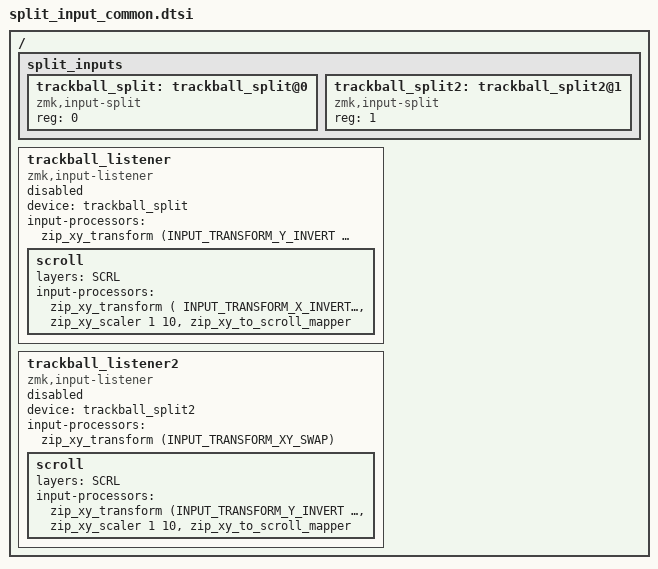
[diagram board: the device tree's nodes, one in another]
#include <dt-bindings/zmk/input_transform.h>
#include <input/processors.dtsi>

#define U_BASE   0
#define U_EXTRA  1
#define U_TAP    2
#define U_BUTTON 3
#define U_NAV    4
#define U_MOUSE  5
#define U_MEDIA  6
#define U_NUM    7
#define U_SYM    8
#define U_FUN    9

/ {
  split_inputs {
    #address-cells = <1>;
    #size-cells = <0>;

    trackball_split: trackball_split@0 {
      compatible = "zmk,input-split";
      reg = <0>;
    };
    trackball_split2: trackball_split2@1 {
      compatible = "zmk,input-split";
      reg = <1>;
    };
  };

  trackball_listener: trackball_listener {
    compatible = "zmk,input-listener";
    status = "disabled";
    device = <&trackball_split>;
    input-processors = <&zip_xy_transform (INPUT_TRANSFORM_Y_INVERT | INPUT_TRANSFORM_X_INVERT | INPUT_TRANSFORM_XY_SWAP )>;
    scroll {
      layers = <SCRL>;
      input-processors = <&zip_xy_transform ( INPUT_TRANSFORM_X_INVERT | INPUT_TRANSFORM_XY_SWAP)>, <&zip_xy_scaler 1 10>, <&zip_xy_to_scroll_mapper>;
    };

  };
  trackball_listener2: trackball_listener2 {
    compatible = "zmk,input-listener";
    status = "disabled";
    device = <&trackball_split2>;
    input-processors = <&zip_xy_transform (INPUT_TRANSFORM_XY_SWAP)>;

    scroll {
      layers = <SCRL>;
      input-processors = <&zip_xy_transform (INPUT_TRANSFORM_Y_INVERT | INPUT_TRANSFORM_XY_SWAP)>, <&zip_xy_scaler 1 10>, <&zip_xy_to_scroll_mapper>;
    };

  };
};
